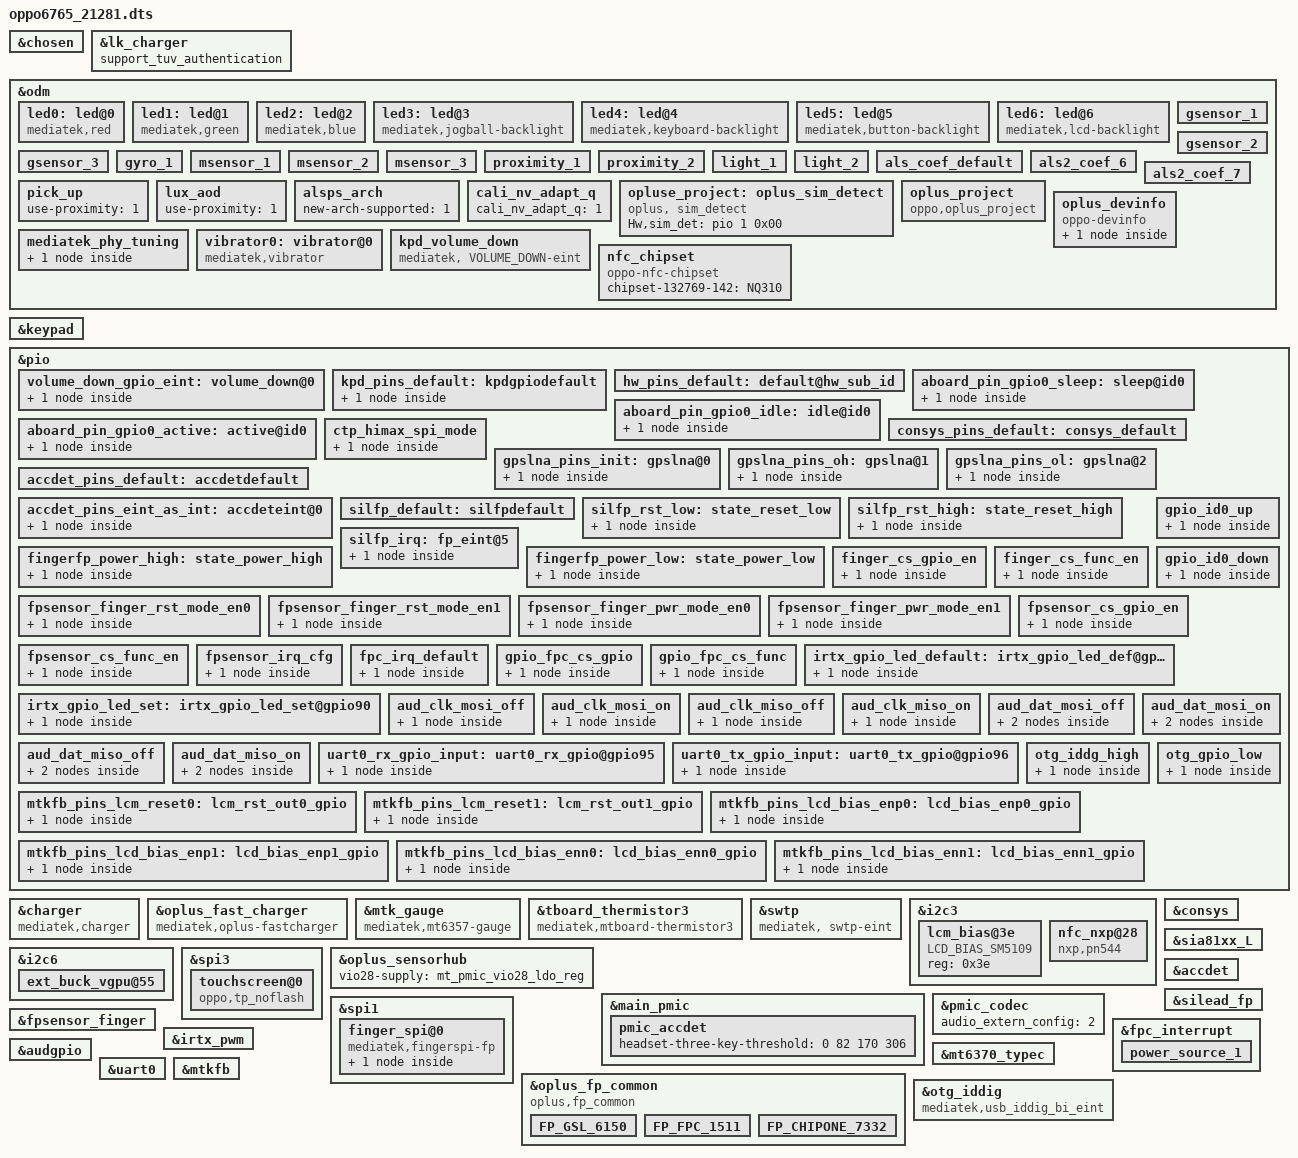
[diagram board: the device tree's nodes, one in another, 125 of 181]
// SPDX-License-Identifier: GPL-2.0+
/*
 * Copyright (c) 2019 MediaTek Inc.
 *
 */

#include <dt-bindings/interrupt-controller/arm-gic.h>
#include <dt-bindings/interrupt-controller/irq.h>
#include <dt-bindings/pinctrl/mt6765-pinfunc.h>
#include <dt-bindings/clock/mt6765-clk.h>

/dts-v1/;
/plugin/;

/* chosen */
&chosen {

	/* fpga may has no lk, we need to specify display info here */
	/* fb buffer is reserved using this dts by memory node above */
	atag,videolfb-fb_base_h = <0x0>;
	atag,videolfb-fb_base_l = <0x5e605000>;
	atag,videolfb-islcmfound = <1>;
	/* because no lk, so lcm is not inited */
	atag,videolfb-islcm_inited = <0>;
	atag,videolfb-fps= <6000>;
	atag,videolfb-vramSize= <0x017bb000>;
	atag,videolfb-lcmname= "nt35695B_fhd_dsi_cmd_auo_rt5081_drv";
};

&lk_charger{
	support_tuv_authentication;
};

&odm {
	led0:led@0 {
		compatible = "mediatek,red";
		led_mode = <0>;
		data = <1>;
		pwm_config = <0 0 0 0 0>;
	};
	led1:led@1 {
		compatible = "mediatek,green";
		led_mode = <0>;
		data = <1>;
		pwm_config = <0 0 0 0 0>;
	};
	led2:led@2 {
		compatible = "mediatek,blue";
		led_mode = <0>;
		data = <1>;
		pwm_config = <0 0 0 0 0>;
	};
	led3:led@3 {
		compatible = "mediatek,jogball-backlight";
		led_mode = <0>;
		data = <1>;
		pwm_config = <0 0 0 0 0>;
	};
	led4:led@4 {
		compatible = "mediatek,keyboard-backlight";
		led_mode = <0>;
		data = <1>;
		pwm_config = <0 0 0 0 0>;
	};
	led5:led@5 {
		compatible = "mediatek,button-backlight";
		led_mode = <0>;
		data = <1>;
		pwm_config = <0 0 0 0 0>;
	};
	led6:led@6 {
		compatible = "mediatek,lcd-backlight";
//#ifndef OPLUS_BUG_STABILITY
		//led_mode = <5>;
//#else
		led_mode = <4>;
//#endif
		data = <1>;
		pwm_config = <0 3 0 0 0>;
	};
/*sensor start */
	/*
	enum {
		LIS3DH,
		LSM6DS3,
		BMI160,
		LIS2HH12,
		LSM6DSM,
		BMI2XY,
		LSM6DSO,
		BMA2X2,
		KX022,
		SC7A20,
		MC34X9,
		STK832X,
		BMA4XY,
	};
	*/
    gsensor_1: gsensor_1 {
		status = "okay";
		sensor_name = <9>;//SC7A20
		i2c_num = <0>;
		i2c_addr = <0x11>;
		direction = <1>;
		eint_num = <12>;
		step_count_7_en = <1>;
		config_miso = <1>;
		correct_y_bias = <1>;
	};
	gsensor_2: gsensor_2 {
		status = "okay";
		sensor_name = <3>;//LIS2HH12
		i2c_num = <0>;
		i2c_addr = <0x68>;
		direction = <3>;
		eint_num = <12>;
		step_count_7_en = <1>;
		config_miso = <1>;
		correct_y_bias = <1>;
	};
	gsensor_3: gsensor_3 {
		status = "okay";
		sensor_name = <0>;//LIS3DH
		i2c_num = <0>;
		i2c_addr = <0x68>;
		direction = <0>;
		eint_num = <12>;
		step_count_7_en = <1>;
		config_miso = <1>;
		correct_y_bias = <1>;
	};
	gyro_1: gyro_1 {
		status = "okay";
		sensor_name = <12>;//BMA4XY
		i2c_num = <0>;
		i2c_addr = <0x68>;
		direction = <10>;
		eint_num = <12>;
		step_count_7_en = <1>;
		config_miso = <1>;
		correct_y_bias = <1>;
	};
	/*
	enum {
		AKM09911,
		MMC3530,
		MMC5603,
		MXG4300,
		AF6133,
	};
	*/
	msensor_1: msensor_1 {
		status = "okay";
		sensor_name = <0>;//AKM09918
		i2c_num = <0>;
		i2c_addr = <0x0c>;
		direction = <1>;
		eint_num = <0>;
	};

	msensor_2: msensor_2 {
		status = "okay";
		sensor_name = <2>;//MMC5603
		i2c_num = <0>;
		i2c_addr = <0x30>;
		direction = <1>;
		eint_num = <0>;
	};
	msensor_3: msensor_3 {
		status = "okay";
		sensor_name = <1>;//MMC3530
		i2c_num = <0>;
		i2c_addr = <0x30>;
		direction = <3>;
		eint_num = <0>;
	};
	/*
	enum {
		TMD2725,
		APSD9922,
		STK3335,
		STK3331,
		STK2232,
		TCS3701,
		STK32600,
		STK33502,
	};
	*/
	proximity_1: proximity_1 {
		status = "okay";
		sensor_name = <7>;//STK33502
		i2c_num = <0>;
		i2c_addr = <0x46>;
		direction = <4>;
		eint_num = <6>;
		low_step = <300>;
		high_step = <400>;
		low_limit = <650>;
		high_limit = <1050>;
		dirty_low_step = <300>;
		dirty_high_step = <400>;
		ps_dirty_limit = <1800>;
		ps_ir_limit = <2000>;
		ps_adjust_min = <0>;
		ps_adjust_max = <1850>;
		sampling_count = <5>;
		step_max = <400>;
		step_min = <100>;
		step_div = <2000>;
		anti_shake_delta = <70>;
		dynamic_cali_max = <2000>;
		raw2offset_radio = <1000>;
		offset_max = <60000>;
		offset_range_min = <0>;
		offset_range_max = <65534>;
		force_cali_limit = <2000>;
		cali_jitter_limit = <20>;
		cal_offset_margin = <3000>;
	};
	proximity_2: proximity_2 {
		status = "okay";
		sensor_name = <3>;//STK3331
		i2c_num = <0>;
		i2c_addr = <71>;
		direction = <4>;
		eint_num = <10>;
		low_step = <300>;
		high_step = <400>;
		low_limit = <650>;
		high_limit = <1050>;
		dirty_low_step = <200>;
		dirty_high_step = <300>;
		ps_dirty_limit = <1800>;
		ps_ir_limit = <2000>;
		ps_adjust_min = <0>;
		ps_adjust_max = <1850>;
		sampling_count = <5>;
		step_max = <400>;
		step_min = <100>;
		step_div = <1500>;
		anti_shake_delta = <80>;
		dynamic_cali_max = <5000>;
		raw2offset_radio = <1000>;
		offset_max = <60000>;
		offset_range_min = <0>;
		offset_range_max = <65534>;
		force_cali_limit = <2000>;
		cali_jitter_limit = <20>;
		cal_offset_margin = <3000>;
		parameter-number = <4>;
		sensor-reg  = <0x03 0xC0
				0xA1 0x0E>;
	};
	light_1: light_1 {
		status = "okay";
		sensor_name = <7>;//STK33502
		i2c_num = <0>;
		i2c_addr = <0x46>;
		direction = <4>;
		eint_num = <6>;
		als_ratio = <65>;
		als_buffer_length =<8>;
		als_type = <1>;//<1-normal;2-under screen;3-normal needed compensation>
		device_name = "stk33502";
	};
	light_2: light_2 {
		status = "okay";
		sensor_name = <3>;//STK3331
		i2c_num = <0>;
		i2c_addr = <71>;
		direction = <4>;
		eint_num = <10>;
		als_ratio = <200>;
		device_name = "stk3331";
		als_buffer_length =<5>;
		als_type = <1>;
	};
	als_coef_default:als_coef_default{
		status = "okay";
		coef_A = <8400>;
		coef_B = <34500>;
		coef_C = <900>;
		coef_D = <2300>;
		coef_E = <12000>;
        };
	als2_coef_6:als2_coef_6 {
		status = "okay";
		coef_A = <20000>;
		coef_B = <68400>;
		coef_C = <3800>;
		coef_D = <12300>;
		coef_E = <17000>;
	};
	als2_coef_7:als2_coef_7 {
		status = "okay";
		coef_A = <30000>;
		coef_B = <68400>;
		coef_C = <3800>;
		coef_D = <12300>;
		coef_E = <17000>;
	};
	pick_up: pick_up {
		status = "okay";
		use-proximity = <1>;
	};
	lux_aod: lux_aod {
		status = "okay";
		use-proximity = <1>;
	};
	alsps_arch: alsps_arch {
		status = "okay";
		new-arch-supported = <1>;
	};
	cali_nv_adapt_q: cali_nv_adapt_q {
		status = "okay";
		cali_nv_adapt_q = <1>;
	};
/*sensor end */
/*VNDOR_EDIT oppo project start */
	opluse_project:oplus_sim_detect {
		compatible = "oplus, sim_detect";
		Hw,sim_det = <&pio 1 0x00>;
	};

	oplus_project:oplus_project {
		compatible = "oppo,oplus_project";
	};

	oplus_devinfo:oplus_devinfo {
		compatible = "oppo-devinfo";
		main-sub {
			use_tristate_gpio;
			compatible = "hw-match, main-sub";
			aboard-gpio0 = <&pio 160 0x00>;
			aboard-patterns = <0 1 0 0>;
			/*main board*/
			match-projects = <21281 21282 21283 21285>;
		};
	};
/*2021/04/21, Add eye diag parameter */
	mediatek_phy_tuning:mediatek_phy_tuning {
		phy_tuning {
			compatible = "mediatek,phy_eye";
			device_vrt_ref = <7>;
			device_term_ref = <7>;
			device_rev6_ref = <3>;
			host_vrt_ref = <7>;
			host_term_ref = <2>;
			host_rev6_ref = <3>;
	};
};
/*2021/04/21, Add eye diag parameter */
	vibrator0:vibrator@0 {
		compatible = "mediatek,vibrator";
		/*
		vib_timer = <25>;
		vib_limit = <9>;
		vib_vol= <9>;
		*/
		vib_timer = <30>;
		vib_limit = <0>;
		vib_vol= <11>;
	};
//ifdef OPLUS_BUG_STABILITY
	kpd_volume_down:kpd_volume_down {
		compatible = "mediatek, VOLUME_DOWN-eint";
		interrupt-parent = <&pio>;
		interrupts = <94 IRQ_TYPE_EDGE_FALLING 94 0>;
		debounce = <32000>;
		status = "okay";
	};
//#endif /*OPLUS_BUG_STABILITY*/

//#ifdef OPLUS_FEATURE_NFC_CONSOFT
    nfc_chipset:nfc_chipset {
        compatible = "oppo-nfc-chipset";
        chipset-132769-142 = "NQ310";
    };
//#endif /* OPLUS_FEATURE_NFC_CONSOFT */
};
//ifdef OPLUS_BUG_STABILITY
&keypad {
	keypad,volume-down	= <&pio 94 0x00>;
        pinctrl-names = "default", "volume_down_as_int";
        pinctrl-0 = <&kpd_pins_default>;
        pinctrl-1 = <&volume_down_gpio_eint>;
	status = "okay";
};

&pio {
	volume_down_gpio_eint:volume_down@0{
		pins_cmd_dat {
			pinmux = <PINMUX_GPIO94__FUNC_GPIO94>;
			slew-rate = <0>;  /*direction 0:in, 1:out*/
			input-enable;
		};
	};
	kpd_pins_default: kpdgpiodefault {
                pins_cmd_dat {
                        pinmux = <PINMUX_GPIO93__FUNC_KPCOL0>;
                        bias-pull-up = <MTK_PUPD_SET_R1R0_10>;
                        output-low;
                        input-schmitt-enable;
                };
        };
};
//#endif /*OPLUS_BUG_STABILITY*/

&oplus_devinfo {
	pinctrl-names = "default", "aboard_gpio0_sleep", "aboard_gpio0_active", "aboard_gpio0_idle";
	pinctrl-0 = <&hw_pins_default>;
	pinctrl-1 = <&aboard_pin_gpio0_sleep>;
	pinctrl-2 = <&aboard_pin_gpio0_active>;
	pinctrl-3 = <&aboard_pin_gpio0_idle>;
};

&pio {
	hw_pins_default:default@hw_sub_id {
	};

	aboard_pin_gpio0_sleep:sleep@id0 {
		pins_cmd_dat {
			pinmux = <PINMUX_GPIO160__FUNC_GPIO160>;
			input;
			bias-pull-down;
			input-enable;
		};
	};

	aboard_pin_gpio0_active:active@id0 {
		pins_cmd_dat {
			pinmux = <PINMUX_GPIO160__FUNC_GPIO160>;
			input;
			bias-pull-up;
			input-enable;
		};
	};

	aboard_pin_gpio0_idle:idle@id0 {
		pins_cmd_dat {
			pinmux = <PINMUX_GPIO160__FUNC_GPIO160>;
			slew-rate = <0>;
			bias-disable;
			input-enable;
		};
	};
};

//#idef OPLUS_CHARGER_BASIC
&charger {
	compatible = "mediatek,charger";
		//pinctrl-names = "default", "charger_gpio_as_output_low", "charger_gpio_as_output_high", "ship_sleep", "ship_active", "shortc_active";
		//pinctrl-0 = <&charger_pins_default>;
		//pinctrl-1 = <&charger_pins_eint_output0>;
		//pinctrl-2 = <&charger_pins_eint_output1>;
		//pinctrl-3 = <&ship_sleep_gpio>;
		//pinctrl-4 = <&ship_active_gpio>;
		//pinctrl-5 = <&shortc_active_gpio>;

		//for oppo chg framework:
		qcom,input_current_charger_ma = <2000>;
		qcom,input_current_cdp_ma = <1500>;
		qcom,input_current_usb_ma = <500>;
		qcom,input_current_led_ma = <1200>;
		qcom,input_current_led_ma_forcmcc = <500>;
		qcom,input_current_camera_ma = <1200>;
		qcom,input_current_calling_ma = <1200>;
		
		qcom,input_current_led_ma_high = <1200>;
		qcom,input_current_led_ma_warm = <1500>;
		qcom,input_current_led_ma_normal = <2000>;

		qcom,led_high_bat_decidegc = <370>;
		qcom,led_warm_bat_decidegc = <350>;

		qcom,iterm_disabled = <0>;
		qcom,iterm_ma = <205>;
		qcom,recharge-mv = <100>;

		qcom,batt_capacity_mah = <4230>; /*typical capacity*/
		//qcom,batt_capacity_mah = <3900>; /*rated capacity*/

		qcom,removed_bat_decidegc = <190>;  /* < -19C */

		qcom,cold_bat_decidegc = <20>;  /* -2C ~ 0C */
		qcom,temp_cold_vfloat_mv = <3980>;
		qcom,temp_cold_fastchg_current_ma = <350>;

		qcom,little_cold_bat_decidegc = <0>;	/* 0C ~ 5C */
		qcom,temp_little_cold_vfloat_mv = <4385>;
		qcom,temp_little_cold_fastchg_current_ma_high = <550>;
		qcom,temp_little_cold_fastchg_current_ma_low = <550>;
		qcom,temp_little_cold_fastchg_current_ma = <550>;
		monet,temp_little_cold_usbchg_current_ma_high = <650>;
		monet,temp_little_cold_usbchg_current_ma_low = <650>;
		monet,temp_little_cold_usbchg_current_ma = <650>;

		qcom,cool_bat_decidegc = <50>;	/* 5C ~ 12C */
		qcom,temp_cool_vfloat_mv = <4385>;
		qcom,temp_cool_fastchg_current_ma_high = <1150>;
		qcom,temp_cool_fastchg_current_ma_low = <550>;
		monet,temp_cool_usbchg_current_ma_high = <650>;
		monet,temp_cool_usbchg_current_ma_low = <550>;

		qcom,little_cool_bat_decidegc = <120>;	/* 12C ~ 16C */
		qcom,temp_little_cool_vfloat_mv = <4385>;
		qcom,temp_little_cool_fastchg_current_ma = <1700>;
		monet,temp_little_cool_usbchg_current_ma = <550>;

		qcom,normal_bat_decidegc = <160>;	/* 16C ~ 45C */
		qcom,temp_normal_fastchg_current_ma = <2200>;
		monet,temp_normal_usbchg_current_ma = <550>;
		qcom,temp_normal_vfloat_mv = <4385>;

		qcom,warm_bat_decidegc = <440>;		/* 44C ~ 53C */ /*8pin Bat Vooc project need add 3 degree C*/
		qcom,temp_warm_vfloat_mv = <4130>;
		qcom,temp_warm_fastchg_current_ma = <1150>;
		monet,temp_warm_usbchg_current_ma = <550>;
		qcom,temp_warm_fastchg_current_ma_led_on = <500>;

		qcom,hot_bat_decidegc = <530>;  /* > 53C */

		qcom,non_standard_vfloat_mv = <3980>;
		qcom,non_standard_fastchg_current_ma = <512>;

		qcom,short_c_bat_cv_mv = <4330>;
		qcom,short_c_bat_vfloat_mv = <3800>;
		qcom,short_c_bat_fastchg_current_ma = <512>;
		qcom,short_c_bat_vfloat_sw_limit = <3750>;

		qcom,cold_vfloat_sw_limit = <3930>;
		qcom,little_cold_vfloat_sw_limit = <4335>;
		qcom,cool_vfloat_sw_limit = <4335>;
		qcom,little_cool_vfloat_sw_limit = <4335>;
		qcom,normal_vfloat_sw_limit = <4335>;
		qcom,warm_vfloat_sw_limit = <4080>;
		qcom,non_standard_vfloat_sw_limit = <3930>;

		qcom,max_chg_time_sec = <36000>;
		qcom,charger_hv_thr = <5800>;
		qcom,charger_recv_thr = <5800>;
		qcom,charger_lv_thr = <3400>;
		qcom,vbatt_full_thr = <4400>;
		qcom,vbatt_hv_thr = <4500>;

		qcom,vfloat_step_mv = <10>;
		qcom,non_standard_vfloat_over_sw_limit = <4000>;
		qcom,cold_vfloat_over_sw_limit = <4000>;
		qcom,little_cold_vfloat_over_sw_limit = <4400>;
		qcom,cool_vfloat_over_sw_limit = <4400>;
		qcom,little_cool_vfloat_over_sw_limit = <4400>;
		qcom,normal_vfloat_over_sw_limit = <4400>;
		qcom,warm_vfloat_over_sw_limit = <4150>;

		qcom,vbatt_power_off = <3300>;
		qcom,vbatt_soc_1 = <3410>;
		qcom,vooc_project = <0>;
		qcom,vbatt_num = <1>;

		qcom,normal_vterm_hw_inc = <150>;
		qcom,non_normal_vterm_hw_inc = <10>;

		qcom,ff1_normal_fastchg_ma = <1088>;
		qcom,ffc2_normal_fastchg_ma = <780>;/*16C~35c*/
		qcom,ffc2_temp_warm_decidegc = <350>;
		qcom,ffc2_warm_fastchg_ma = <840>;/*35C~40c*/
		qcom,ffc2_temp_high_decidegc = <400>;
		qcom,ffc2_temp_low_decidegc = <120>;
		qcom,ff1_exit_step_ma = <488>;
		qcom,ff1_warm_exit_step_ma = <418>;
		qcom,ffc2_exit_step_ma = <180>;
		qcom,ffc2_warm_exit_step_ma = <170>;

		qcom,ffc_normal_vfloat_sw_limit = <4430>;
		qcom,ffc_temp_normal_vfloat_mv = <4500>;
		qcom,ffc_normal_vfloat_over_sw_limit = <4500>;

		qcom,default_iterm_ma = <205>;
		qcom,default_temp_normal_fastchg_current_ma = <2200>;
		qcom,default_normal_vfloat_sw_limit = <4335>;
		qcom,default_temp_normal_vfloat_mv = <4385>;
		qcom,default_normal_vfloat_over_sw_limit = <4400>;

		//for 2nd chip:
		qcom,iterm_ma_2nd = <300>;
		qcom,recharge-mv_2nd = <121>;

		qcom,temp_little_cold_vfloat_mv_2nd = <4391>;	/* 0C ~ 5C */
		qcom,temp_cool_vfloat_mv_2nd = <4391>;	/* 5C ~ 12C */
		qcom,temp_little_cool_vfloat_mv_2nd = <4391>;	/* 12C ~ 16C */
		qcom,temp_normal_vfloat_mv_2nd = <4391>;	/* 16C ~ 45C */

		qcom,little_cold_vfloat_over_sw_limit_2nd = <4395>;
		qcom,cool_vfloat_over_sw_limit_2nd = <4395>;
		qcom,little_cool_vfloat_over_sw_limit_2nd = <4395>;
		qcom,normal_vfloat_over_sw_limit_2nd = <4395>;

		qcom,default_iterm_ma_2nd = <300>;
		qcom,default_temp_normal_vfloat_mv_2nd = <4391>;
		qcom,default_normal_vfloat_over_sw_limit_2nd = <4395>;

		//for control:
		//qcom,suspend_after_full;
		qcom,check_batt_full_by_sw;
		//qcom,external_gauge;
		qcom,chg_ctrl_by_calling;
		qcom,chg_ctrl_by_lcd;
		qcom,chg_ctrl_by_camera;
		qcom,sw_vfloat_over_protect_enable;
		//qcom,ffc_support;

		//GPIO config:
		//qcom,chargerid_switch-gpio = <&pio 97 0x00>;
		//qcom,ship-gpio = <&pio 155 0x00>;
		//qcom,shortc-gpio = <&pio 77 0x00>;
};

&oplus_fast_charger {
	compatible = "mediatek,oplus-fastcharger";
		//pinctrl-names = "default", "charger_gpio_as_output_low", "charger_gpio_as_output_high", "ship_sleep", "ship_active", "shortc_active";
		//pinctrl-0 = <&charger_pins_default>;
		//pinctrl-1 = <&charger_pins_eint_output0>;
		//pinctrl-2 = <&charger_pins_eint_output1>;
		//pinctrl-3 = <&ship_sleep_gpio>;
		//pinctrl-4 = <&ship_active_gpio>;
		//pinctrl-5 = <&shortc_active_gpio>;

		//for oppo chg framework:
		qcom,input_current_charger_ma = <2000>;
		qcom,input_current_cdp_ma = <1500>;
		qcom,input_current_usb_ma = <500>;
		qcom,input_current_led_ma = <1200>;
		qcom,input_current_led_ma_forcmcc = <500>;
		qcom,input_current_camera_ma = <1200>;
		qcom,input_current_calling_ma = <1200>;

		qcom,input_current_led_ma_high = <1000>;
		qcom,input_current_led_ma_warm = <1500>;
		qcom,input_current_led_ma_normal = <2000>;

		qcom,led_high_bat_decidegc = <370>;
		qcom,led_warm_bat_decidegc = <340>;

		qcom,iterm_disabled = <0>;
		qcom,iterm_ma = <265>;
		qcom,recharge-mv = <115>;

		qcom,batt_capacity_mah = <5000>; /*typical capacity*/
		//qcom,batt_capacity_mah = <3900>; /*rated capacity*/

		qcom,removed_bat_decidegc = <190>;  /* < -19C */

		qcom,cold_bat_decidegc = <20>;  /* -2C ~ 0C */
		qcom,temp_cold_vfloat_mv = <3980>;
		qcom,temp_cold_fastchg_current_ma = <350>;

		qcom,little_cold_bat_decidegc = <0>;	/* 0C ~ 5C */
		qcom,temp_little_cold_vfloat_mv = <4435>;
		qcom,temp_little_cold_fastchg_current_ma_high = <650>;
		qcom,temp_little_cold_fastchg_current_ma_low = <650>;
		qcom,temp_little_cold_fastchg_current_ma = <650>;
		monet,temp_little_cold_usbchg_current_ma_high = <650>;
		monet,temp_little_cold_usbchg_current_ma_low = <650>;
		monet,temp_little_cold_usbchg_current_ma = <650>;

		qcom,cool_bat_decidegc = <50>;	/* 5C ~ 12C */
		qcom,temp_cool_vfloat_mv = <4435>;
		qcom,temp_cool_fastchg_current_ma_high = <1350>;
		qcom,temp_cool_fastchg_current_ma_low = <650>;
		monet,temp_cool_usbchg_current_ma_high = <650>;
		monet,temp_cool_usbchg_current_ma_low = <550>;

		qcom,little_cool_bat_decidegc = <120>;	/* 12C ~ 16C */
		qcom,temp_little_cool_vfloat_mv = <4435>;
		qcom,temp_little_cool_fastchg_current_ma = <2050>;
		monet,temp_little_cool_usbchg_current_ma = <550>;

		qcom,normal_bat_decidegc = <160>;	/* 16C ~ 45C */
		qcom,temp_normal_fastchg_current_ma = <2200>;
		monet,temp_normal_usbchg_current_ma = <550>;
		qcom,temp_normal_vfloat_mv = <4435>;

		qcom,warm_bat_decidegc = <450>;		/* 45C ~ 53C */ /*8pin Bat Vooc project need add 3 degree C*/
		qcom,temp_warm_vfloat_mv = <4130>;
		qcom,temp_warm_fastchg_current_ma = <1350>;
		monet,temp_warm_usbchg_current_ma = <550>;
		qcom,temp_warm_fastchg_current_ma_led_on = <500>;

		qcom,hot_bat_decidegc = <530>;  /* > 53C */

		qcom,non_standard_vfloat_mv = <3980>;
		qcom,non_standard_fastchg_current_ma = <512>;

		qcom,short_c_bat_cv_mv = <4330>;
		qcom,short_c_bat_vfloat_mv = <3800>;
		qcom,short_c_bat_fastchg_current_ma = <512>;
		qcom,short_c_bat_vfloat_sw_limit = <3750>;

		qcom,cold_vfloat_sw_limit = <3930>;
		qcom,little_cold_vfloat_sw_limit = <4380>;
		qcom,cool_vfloat_sw_limit = <4380>;
		qcom,little_cool_vfloat_sw_limit = <4380>;
		qcom,normal_vfloat_sw_limit = <4380>;
		qcom,warm_vfloat_sw_limit = <4080>;
		qcom,non_standard_vfloat_sw_limit = <3930>;

		qcom,max_chg_time_sec = <36000>;
		qcom,charger_hv_thr = <9800>;
		qcom,charger_recv_thr = <9800>;
		qcom,charger_lv_thr = <3400>;
		qcom,vbatt_full_thr = <4400>;
		qcom,vbatt_hv_thr = <4550>;

		qcom,vfloat_step_mv = <10>;
		qcom,non_standard_vfloat_over_sw_limit = <4000>;
		qcom,cold_vfloat_over_sw_limit = <4000>;
		qcom,little_cold_vfloat_over_sw_limit = <4450>;
		qcom,cool_vfloat_over_sw_limit = <4450>;
		qcom,little_cool_vfloat_over_sw_limit = <4450>;
		qcom,normal_vfloat_over_sw_limit = <4450>;
		qcom,warm_vfloat_over_sw_limit = <4150>;

		qcom,vbatt_power_off = <3300>;
		qcom,vbatt_soc_1 = <3410>;
		qcom,vooc_project = <0>;
		qcom,vbatt_num = <1>;

		qcom,normal_vterm_hw_inc = <150>;
		qcom,non_normal_vterm_hw_inc = <10>;

		qcom,ff1_normal_fastchg_ma = <1088>;
		qcom,ffc2_normal_fastchg_ma = <780>;/*16C~35c*/
		qcom,ffc2_temp_warm_decidegc = <350>;
		qcom,ffc2_warm_fastchg_ma = <840>;/*35C~40c*/
		qcom,ffc2_temp_high_decidegc = <400>;
		qcom,ffc2_temp_low_decidegc = <120>;
		qcom,ff1_exit_step_ma = <488>;
		qcom,ff1_warm_exit_step_ma = <418>;
		qcom,ffc2_exit_step_ma = <180>;
		qcom,ffc2_warm_exit_step_ma = <170>;

		qcom,ffc_normal_vfloat_sw_limit = <4430>;
		qcom,ffc_temp_normal_vfloat_mv = <4500>;
		qcom,ffc_normal_vfloat_over_sw_limit = <4500>;

		qcom,default_iterm_ma = <265>;
		qcom,default_temp_normal_fastchg_current_ma = <2200>;
		qcom,default_normal_vfloat_sw_limit = <4380>;
		qcom,default_temp_normal_vfloat_mv = <4435>;
		qcom,default_normal_vfloat_over_sw_limit = <4450>;

		//for 2nd chip:
		qcom,iterm_ma_2nd = <300>;
		qcom,recharge-mv_2nd = <121>;

		qcom,temp_little_cold_vfloat_mv_2nd = <4391>;	/* 0C ~ 5C */
		qcom,temp_cool_vfloat_mv_2nd = <4391>;	/* 5C ~ 12C */
		qcom,temp_little_cool_vfloat_mv_2nd = <4391>;	/* 12C ~ 16C */
		qcom,temp_normal_vfloat_mv_2nd = <4391>;	/* 16C ~ 45C */

		qcom,little_cold_vfloat_over_sw_limit_2nd = <4395>;
		qcom,cool_vfloat_over_sw_limit_2nd = <4395>;
		qcom,little_cool_vfloat_over_sw_limit_2nd = <4395>;
		qcom,normal_vfloat_over_sw_limit_2nd = <4395>;

		qcom,default_iterm_ma_2nd = <300>;
		qcom,default_temp_normal_vfloat_mv_2nd = <4391>;
		qcom,default_normal_vfloat_over_sw_limit_2nd = <4395>;

		//for control:
		//qcom,suspend_after_full;
		qcom,check_batt_full_by_sw;
		//qcom,external_gauge;
		qcom,chg_ctrl_by_calling;
		qcom,chg_ctrl_by_lcd;
		qcom,chg_ctrl_by_camera;
		qcom,sw_vfloat_over_protect_enable;
		//qcom,ffc_support;

		//GPIO config:
		//qcom,chargerid_switch-gpio = <&pio 97 0x00>;
		//qcom,ship-gpio = <&pio 155 0x00>;
		//qcom,shortc-gpio = <&pio 77 0x00>;

		qcom,vbatt_pdqc_to_5v_thr = <4420>;
		status = "okay";
};

&mtk_gauge {
	compatible = "mediatek,mt6357-gauge";
	charger = <&mt6370_chg>;
	bootmode = <&chosen>;
	io-channels = <&pmic_auxadc 0x03>,
		<&pmic_auxadc 0x01>,
		<&pmic_auxadc 0x0e>,
		<&pmic_auxadc 0x0f>,
		<&pmic_auxadc 0x10>,
		<&auxadc 3>;
	io-channel-names = "pmic_battery_temp",
		"pmic_battery_voltage",
		"pmic_bif_voltage",
		"pmic_ptim_voltage",
		"pmic_ptim_r",
		"auxadc6-batt_id_v";
	nvmem-cells = <&fg_init>, <&fg_soc>;
	FUELGAGUE_APPLY = <(1)>;
	Enable_Battery_Temp_Compensation = <(1)>;
	Enable_Is_Force_Full = <1>;
	RBAT_PULL_UP_R = <(12000)>;
	RBAT_PULL_UP_VOLT = <(1800)>;
	status = "okay";
};
//#endif /* OPLUS_CHARGER_BASIC */

&tboard_thermistor3{
		compatible = "mediatek,mtboard-thermistor3";
		io-channels = <&auxadc 4>;
		io-channel-names = "thermistor-ch2";
		interconnects = <&auxadc 4>;
		use_new_ntc_table;
};

//#ifdef OPLUS_BUG_COMPATIBILITY
&swtp {
		compatible = "mediatek, swtp-eint";
	};
//#endif /*OPLUS_BUG_COMPATIBILITY*/

&i2c3 {
//#ifndef OPLUS_BUG_STABILITY
//	ext_buck_lp4@57 {
//		regulator-name ="ext_buck_vdd2";
//		regulator-min-microvolt = <300000>;
//		regulator-max-microvolt = <1300000>;
//		vsel_pin = <0>;
//	};
//
//	ext_buck_lp4x@50 {
//		regulator-name ="ext_buck_vddq";
//		regulator-min-microvolt = <300000>;
//		regulator-max-microvolt = <1300000>;
//		vsel_pin = <1>;
//	};
//#else
	lcm_bias@3e{
		   compatible = "LCD_BIAS_SM5109","LCD_BIAS_OCP2130";
		   reg = <0x3e>;
		   status = "okay";
	};
//#endif
};

//#ifdef OPLUS_FEATURE_NFC_BRINGUP
&i2c3 {
       status = "okay";
       nfc_nxp@28 {
               compatible = "nxp,pn544";
               reg = <0x28>;
               nxp,pn544-irq = <&pio 97 0x0>;
               nxp,pn544-ven = <&pio 98 0x0>;
               nxp,pn544-fw-dwnld = <&pio 170 0x0>;
               //pn544-clkreq = <&pio 89 0x0>;
               interrupt-parent = <&pio>;
       };
};
//#endif /* OPLUS_FEATURE_NFC_BRINGUP */

&i2c6 {
	ext_buck_vgpu@55 {
		regulator-name ="ext_buck_vgpu";
		regulator-min-microvolt = <300000>;
		regulator-max-microvolt = <1300000>;
		vsel_pin = <2>;
	};
};

/* TOUCH start */

&spi3 {
	status = "ok";
  	touchscreen@0 {
		compatible = "oppo,tp_noflash";
		reg = <0>; //Same as CS ID
		chip-name = "OPPO_TP_NOFLASH";
		status = "ok";

        //chip_name_ilitek_9882n = "NF_ILI9881H";

		spi-max-frequency = <9600000>;
		interrupt-parent = <&pio>;
		interrupts = <0 IRQ_TYPE_EDGE_FALLING 0 0>;
		irq-gpio = <&pio 0 0x2002>;
		reset-gpio = <&pio 174 0>;

		platform_support_project = <21281 21282 21283>;
		platform_support_project_dir = <21281 21281 21281>;
		platform_support_project_commandline = "default_commandline", "default_commandline", "default_commandline";

		touchpanel,max-num-support = <10>;
		touchpanel,tx-rx-num = <18 32>;
		touchpanel,panel-coords = <720 1600>;
		touchpanel,display-coords = <720 1600>;
		touchpanel,touchmajor-limit = <0 54>;

		pinctrl-names = "default";
		pinctrl-0 = <&ctp_himax_spi_mode>;

		incell_screen;
		fw_edge_limit_support;
		black_gesture_support;
		charger_pump_support;
		headset_pump_support;
		esd_handle_support;
		//spurious_fingerprint_support;
		//lcd_trigger_fp_check;
		black_gesture_test_support;
		noflash_support;
		smart_gesture_support;
		pressure_report_support;
		fw_update_app_support;
		game_switch_support;
		drlimit_remove_support;
		lcd_trigger_load_tp_fw_support;
		freq_hop_simulate_support;
		suspend_gesture_cfg;
		fw_update_in_probe_with_headfile;

		touchpanel,button-type = <4>;
	};
};

&pio {
	ctp_himax_spi_mode: ctp_himax_spi_mode {
		pins_cmd_dat {
			pinmux = <PINMUX_GPIO21__FUNC_SPI3_MI>,
				<PINMUX_GPIO22__FUNC_SPI3_CSB>,
				<PINMUX_GPIO23__FUNC_SPI3_MO>,
				<PINMUX_GPIO24__FUNC_SPI3_CLK>;
			drive-strength = <2>;
		};
	};
};
/* TOUCH end */

/* CONSYS GPIO standardization */
&pio {
	consys_pins_default: consys_default {
	};
	gpslna_pins_init: gpslna@0 {
		pins_cmd_dat {
			pinmux = <PINMUX_GPIO91__FUNC_GPIO91>;
			slew-rate = <0>;
			bias-disable;
			output-low;
		};
	};
	gpslna_pins_oh: gpslna@1 {
		pins_cmd_dat {
			pinmux = <PINMUX_GPIO91__FUNC_GPIO91>;
			slew-rate = <1>;
			output-high;
		};
	};
	gpslna_pins_ol: gpslna@2 {
		pins_cmd_dat {
			pinmux = <PINMUX_GPIO91__FUNC_GPIO91>;
			slew-rate = <1>;
			output-low;
		};
	};
};

//#ifdef OPLUS_FEATURE_SENSOR
&oplus_sensorhub{
	vio28-supply = <&mt_pmic_vio28_ldo_reg>;
	status = "okay";
};
//#endif //OPLUS_FEATURE_SENSOR

&consys {
	pinctrl-names = "default", "gps_lna_state_init",
		"gps_lna_state_oh", "gps_lna_state_ol";
	pinctrl-0 = <&consys_pins_default>;
	pinctrl-1 = <&gpslna_pins_init>;
	pinctrl-2 = <&gpslna_pins_oh>;
	pinctrl-3 = <&gpslna_pins_ol>;
	status = "okay";
};
/* CONSYS end */

&main_pmic {
    pmic_accdet: pmic_accdet {
        headset-three-key-threshold = <0 82 170 306>;
    };
};

&pmic_codec {
	/* this dtsi config for product's special config, AudioHal read ctl 'OPLUS_AUDIO_EXTERN_CONFIG' get the values*
	 * 1st value --> PA type: 0:NXP Pa, 1:Awinic Pa 2:sia81xx Pa*/
	audio_extern_config = <2>;
};

//#ifdef VENDOR_EDIT
&sia81xx_L{
	si,sia_boost_vol_support = <1>;
	sia81xx_audio_extern_config = <2>;
};
//endif

/* accdet start */
&accdet {
	accdet-mic-vol = <6>;
	headset-mode-setting = <0x500 0x500 1 0x1f0 0x800 0x800 0x20 0x44>;
	accdet-plugout-debounce = <1>;
	accdet-mic-mode = <1>;
	headset-eint-level-pol = <8>;
	headset-three-key-threshold = <0 80 220 400>;
	headset-three-key-threshold-CDD = <0 121 192 600>;
	headset-four-key-threshold = <0 58 121 192 400>;
	pinctrl-names = "default", "state_eint_as_int";
	pinctrl-0 = <&accdet_pins_default>;
	pinctrl-1 = <&accdet_pins_eint_as_int>;
	status = "okay";
};
&pio {
	accdet_pins_default: accdetdefault {
	};
	accdet_pins_eint_as_int: accdeteint@0 {
		pins_cmd_dat {
			pinmux = <PINMUX_GPIO9__FUNC_GPIO9>;
			slew-rate = <0>;
			bias-disable;
		};
	};
};
/* accdet end */

//#ifdef OPLUS_FEATURE_FINGERPRINT
/* FINGERPRINT start */
&spi1 {
	#address-cells = <1>;
	#size-cells = <0>;
	status = "okay";
	finger_spi@0 {
		compatible = "mediatek,fingerspi-fp";
		reg = <0>;
		spi-id = <1>;
		spi-max-frequency = <8000000>;
		netlink-event = <30>;
		spi-irq = <122>;
		spi-reg = <0x11010000>;
		goodix,pw_en = <&pio 18 0x00>;
		status = "okay";
		power_source_1 {
			power-mode = <2>;
			power-name = "goodix,pw_en";
			delay-time = <0>;
		};
	};
};

&silead_fp {
        sil,silead_irq = <&pio 5 0x00>;
	sil,ldo_disable = <1>;
        fpc,vdd-en = <&pio 18 0x00>;
        pinctrl-names = "default", "rst-low", "rst-high",
                        "irq-init", "power_high","power_low","finger_cs_gpio","finger_cs_func";
        pinctrl-0 = <&silfp_default>;
        pinctrl-1 = <&silfp_rst_low>;
        pinctrl-2 = <&silfp_rst_high>;
        pinctrl-3 = <&silfp_irq>;
        pinctrl-4 = <&finger_cs_func_en>, <&fingerfp_power_high>;
        pinctrl-5 = <&finger_cs_gpio_en>, <&fingerfp_power_low>;
        status = "okay";
};

&pio {
        silfp_default: silfpdefault {
        };
        silfp_rst_low: state_reset_low {
                pins_cmd_dat {
                        pinmux = <PINMUX_GPIO7__FUNC_GPIO7>;
                        output-low;
                };
        };
        silfp_rst_high: state_reset_high {
                pins_cmd_dat {
                        pinmux = <PINMUX_GPIO7__FUNC_GPIO7>;
                        output-high;
                };
        };
        silfp_irq: fp_eint@5 {
                pins_cmd_dat {
                        pinmux = <PINMUX_GPIO5__FUNC_GPIO5>;
                        input;
                        bias-disable;
                };
        };
        fingerfp_power_high: state_power_high {
                pins_cmd_dat {
                        pinmux = <PINMUX_GPIO20__FUNC_GPIO20>;
                        output-high;
                };
        };
        fingerfp_power_low: state_power_low {
                pins_cmd_dat {
                        pinmux = <PINMUX_GPIO20__FUNC_GPIO20>;
                        output-low;
                };
        };
        finger_cs_gpio_en: finger_cs_gpio_en {
                pins_cmd_dat {
                        pinmux = <PINMUX_GPIO26__FUNC_GPIO26>;
                        output-low;
                };
        };
        finger_cs_func_en: finger_cs_func_en {
                pins_cmd_dat {
                         pinmux = <PINMUX_GPIO26__FUNC_SPI1_A_CSB>;
                         drive-strength = <3>;
                };
        };
};

&oplus_fp_common {
	compatible = "oplus,fp_common"; //Manufacture, and Model
	oplus,fp_gpio_num = <1>;
	oplus,fp_gpio_0 = <&pio 166 0x00>;
	pinctrl-names = "gpio_id0_up", "gpio_id0_down";
	pinctrl-0 = <&gpio_id0_up>;
	pinctrl-1 = <&gpio_id0_down>;
	oplus,one_gpio_for_three_ic = <1>;
	FP_GSL_6150 {
		oplus,fp-id = <0>; /* fp id mapping table Q:0*/
		vendor-chip = <21>; /* please refer to the struct fp_vendor_t in oppo_fp_commmon.n */
		eng-menu = "-1,-1"; /* represents SNR, inclination test item in engineer menu, and 0/1 means off/on */
		chip-name = "S_6150";  /* /proc/fp_id, will be displayed in engineer menu  */
	};
	FP_FPC_1511 {
		oplus,fp-id = <2>; /* fp id mapping table Q:1*/
		vendor-chip = <28>; /* please refer to the struct fp_vendor_t in oppo_fp_commmon.n */
		eng-menu = "-1,-1"; /* represents SNR, inclination test item in engineer menu, and 0/1 means off/on */
		chip-name = "F_1521";  /* /proc/fp_id, will be displayed in engineer menu  */
	};
	FP_CHIPONE_7332 {
		oplus,fp-id = <1>; /* fp id mapping table Q:2*/
		vendor-chip = <24>; /* please refer to the struct fp_vendor_t in oppo_fp_commmon.n */
		eng-menu = "-1,-1"; /* represents SNR, inclination test item in engineer menu, and 0/1 means off/on */
		chip-name = "C_7332";  /* /proc/fp_id, will be displayed in engineer menu  */
	};
};

&pio {
	gpio_id0_up: gpio_id0_up {
		pins_cmd_dat {
			pinmux = <PINMUX_GPIO166__FUNC_GPIO166>;
			input;
			bias-pull-up;
			input-enable;
		};
	};
	gpio_id0_down: gpio_id0_down {
		pins_cmd_dat {
			pinmux = <PINMUX_GPIO166__FUNC_GPIO166>;
			input;
			bias-pull-down;
			input-enable;
		};
	};
};

&fpsensor_finger {
	chipone,ldo_disable = <1>;
	chipone,irq-gpio = <&pio 5 0x00>;
	interrupt-parent = <&pio>;
	interrupts = <5 IRQ_TYPE_EDGE_RISING>;
	debounce = <2 0>;
	pinctrl-names = "fpsensor_finger_rst_low","fpsensor_finger_rst_high","power_low","power_high","fpsensor_cs_gpio","fpsensor_cs_func","irq-init";
	pinctrl-0 = <&fpsensor_finger_rst_mode_en0>;
	pinctrl-1 = <&fpsensor_finger_rst_mode_en1>;
	pinctrl-2 = <&fpsensor_finger_pwr_mode_en0>;
	pinctrl-3 = <&fpsensor_finger_pwr_mode_en1>;
	pinctrl-4 = <&fpsensor_cs_gpio_en>;
	pinctrl-5 = <&fpsensor_cs_func_en>;
	pinctrl-6 = <&fpsensor_irq_cfg>;
	status = "okay";
};

&pio {
	fpsensor_finger_rst_mode_en0: fpsensor_finger_rst_mode_en0 {
		pins_cmd_dat {
			pinmux = <PINMUX_GPIO7__FUNC_GPIO7>;
			output-low;
		};
	};
	fpsensor_finger_rst_mode_en1: fpsensor_finger_rst_mode_en1 {
		pins_cmd_dat {
			pinmux = <PINMUX_GPIO7__FUNC_GPIO7>;
			output-high;
		};
	};

	fpsensor_finger_pwr_mode_en0: fpsensor_finger_pwr_mode_en0 {
		pins_cmd_dat {
			pinmux = <PINMUX_GPIO20__FUNC_GPIO20>;
			output-low;
		};
	};
	fpsensor_finger_pwr_mode_en1: fpsensor_finger_pwr_mode_en1 {
		pins_cmd_dat {
			pinmux = <PINMUX_GPIO20__FUNC_GPIO20>;
			output-high;
		};
	};
	fpsensor_cs_gpio_en: fpsensor_cs_gpio_en {
		pins_cmd_dat {
			pinmux = <PINMUX_GPIO26__FUNC_GPIO26>;
			output-low;
		};
	};
	fpsensor_cs_func_en: fpsensor_cs_func_en {
		pins_cmd_dat {
			pinmux = <PINMUX_GPIO26__FUNC_SPI1_A_CSB>;
			drive-strength = <3>;
		};
	};
	fpsensor_irq_cfg: fpsensor_irq_cfg {
		pins_cmd_dat {
			pinmux = <PINMUX_GPIO5__FUNC_GPIO5>;
			input;
			bias-disable;
		};
	};
};

&fpc_interrupt {
	fpc,irq-gpio    = <&pio 5 0x00>;
	fpc,reset-gpio  = <&pio 7 0x00>;
	fpc,vdd-en = <&pio 18 0x00>;
	fpc,gpio_cs = <&pio 26 0x00>;
	fpc,use_gpio_power_enable = <1>;
	pinctrl-names = "irq_default", "fpc_cs_gpio","fpc_cs_func";
	pinctrl-0 = <&fpc_irq_default>/*,<&fpc_pwr_default>*/;
	pinctrl-1 = <&gpio_fpc_cs_gpio>;
	pinctrl-2 = <&gpio_fpc_cs_func>;
	status = "okay";
	power_source_1 {
		power-mode = <2>;
		power-name = "fpc,vdd-en";
		poweron-level = <0>;
		delay-time = <0>;
	};
};

&pio {
	fpc_irq_default: fpc_irq_default {
		pins_cmd_dat {
			pinmux = <PINMUX_GPIO5__FUNC_GPIO5>;
			input;
			bias-pull-up;
		};
	};
	gpio_fpc_cs_gpio: gpio_fpc_cs_gpio {
		pins_cmd_dat {
			pinmux = <PINMUX_GPIO26__FUNC_GPIO26>;
			output-low;
		};
	};
	gpio_fpc_cs_func: gpio_fpc_cs_func {
		pins_cmd_dat {
			pinmux = <PINMUX_GPIO26__FUNC_SPI1_A_CSB>;
			drive-strength = <3>;
		};
	};
};

/* FINGERPRINT end */
//#endif /*OPLUS_FEATURE_FINGERPRINT*/


/* IRTX GPIO end */
&irtx_pwm {
	pinctrl-names = "irtx_gpio_led_default", "irtx_gpio_led_set";
	pinctrl-0 = <&irtx_gpio_led_default>;
	pinctrl-1 = <&irtx_gpio_led_set>;
	status = "okay";
};
&pio {
	irtx_gpio_led_default:irtx_gpio_led_def@gpio90 {
		pins_cmd_dat {
			pinmux = <PINMUX_GPIO90__FUNC_GPIO90>;
			slew-rate = <1>;
			bias-disable;
			output-low;
			input-schmitt-enable = <0>;
		};
	};

	irtx_gpio_led_set:irtx_gpio_led_set@gpio90 {
		pins_cmd_dat {
			pinmux = <PINMUX_GPIO90__FUNC_PWM0>;
			slew-rate = <1>;
			output-high;
		};
	};
};
/* IRTX GPIO Settings -End */

/* AUDIO GPIO standardization */
&audgpio {
	pinctrl-names = "aud_clk_mosi_off",
			"aud_clk_mosi_on",
			"aud_clk_miso_off",
			"aud_clk_miso_on",
			"aud_dat_mosi_off",
			"aud_dat_mosi_on",
			"aud_dat_miso_off",
			"aud_dat_miso_on";
	pinctrl-0 = <&aud_clk_mosi_off>;
	pinctrl-1 = <&aud_clk_mosi_on>;
	pinctrl-2 = <&aud_clk_miso_off>;
	pinctrl-3 = <&aud_clk_miso_on>;
	pinctrl-4 = <&aud_dat_mosi_off>;
	pinctrl-5 = <&aud_dat_mosi_on>;
	pinctrl-6 = <&aud_dat_miso_off>;
	pinctrl-7 = <&aud_dat_miso_on>;

	status = "okay";
};

&pio {
	aud_clk_mosi_off: aud_clk_mosi_off {
		pins_cmd0_dat {
			pinmux = <PINMUX_GPIO136__FUNC_GPIO136>;
		};
	};

	aud_clk_mosi_on: aud_clk_mosi_on {
		pins_cmd0_dat {
			pinmux = <PINMUX_GPIO136__FUNC_AUD_CLK_MOSI>;
		};
	};

	aud_clk_miso_off: aud_clk_miso_off {
		pins_cmd0_dat {
			pinmux = <PINMUX_GPIO140__FUNC_GPIO140>;
		};
	};

	aud_clk_miso_on: aud_clk_miso_on {
		pins_cmd0_dat {
			pinmux = <PINMUX_GPIO140__FUNC_AUD_CLK_MISO>;
		};
	};

	aud_dat_mosi_off: aud_dat_mosi_off {
		pins_cmd1_dat {
			pinmux = <PINMUX_GPIO138__FUNC_GPIO138>;
			input-enable;
			slew-rate = <0>;
			bias-disable;
		};
		pins_cmd2_dat {
			pinmux = <PINMUX_GPIO139__FUNC_GPIO139>;
			input-enable;
			slew-rate = <0>;
			bias-disable;
		};
	};

	aud_dat_mosi_on: aud_dat_mosi_on {
		pins_cmd1_dat {
			pinmux = <PINMUX_GPIO138__FUNC_AUD_DAT_MOSI0>;
		};
		pins_cmd2_dat {
			pinmux = <PINMUX_GPIO139__FUNC_AUD_DAT_MOSI1>;
		};
	};

	aud_dat_miso_off: aud_dat_miso_off {
		pins_cmd1_dat {
			pinmux = <PINMUX_GPIO142__FUNC_GPIO142>;
			input-enable;
			slew-rate = <0>;
			bias-disable;
		};
		pins_cmd2_dat {
			pinmux = <PINMUX_GPIO143__FUNC_GPIO143>;
			input-enable;
			slew-rate = <0>;
			bias-disable;
		};
	};

	aud_dat_miso_on: aud_dat_miso_on {
		pins_cmd1_dat {
			pinmux = <PINMUX_GPIO142__FUNC_AUD_DAT_MISO0>;
		};
		pins_cmd2_dat {
			pinmux = <PINMUX_GPIO143__FUNC_AUD_DAT_MISO1>;
		};
	};
};
/* AUDIO end */

#include "mediatek/rt9471_single.dtsi"
#include "mediatek/sgm41512.dtsi"
#include "mediatek/bq25910.dtsi"
#include "mediatek/bq2589x.dtsi"

&mt6370_typec {
	mt6370pd,intr_gpio_num = <41>; /* direct defined GPIO num */
	mt6370pd,intr_gpio = <&pio 41 0x0>;
};

&uart0 {
	pinctrl-names = "uart0_rx_gpio",
		"uart0_tx_gpio";
	pinctrl-0 = <&uart0_rx_gpio_input>;
	pinctrl-1 = <&uart0_tx_gpio_input>;
	status = "okay";
};
&pio {
	uart0_rx_gpio_input:uart0_rx_gpio@gpio95 {
		pins_cmd_dat {
			pinmux = <PINMUX_GPIO95__FUNC_GPIO95>;
			input-enable;
			bias-pull-down;
		};
	};
	uart0_tx_gpio_input:uart0_tx_gpio@gpio96 {
		pins_cmd_dat {
			pinmux = <PINMUX_GPIO96__FUNC_GPIO96>;
			input-enable;
			bias-pull-down;
		};
	};
};

&otg_iddig {
	compatible = "mediatek,usb_iddig_bi_eint";
	interrupt-parent = <&pio>;
	interrupts = <147 IRQ_TYPE_LEVEL_LOW 147 0>;
	pinctrl-names = "otg_iddg_high","otg_gpio_low";
	pinctrl-0 = <&otg_iddg_high>;
	pinctrl-1 = <&otg_gpio_low>;
};

&pio {
	otg_iddg_high:otg_iddg_high {
		pins_cmd_dat {
			pinmux = <PINMUX_GPIO41__FUNC_IDDIG>;
			input;
			bias-pull-up;
		};
	};

	otg_gpio_low:otg_gpio_low {
		pins_cmd_dat {
			pinmux = <PINMUX_GPIO41__FUNC_GPIO41>;
			output-low;
		};
	};
};


//#ifdef OPLUS_BUG_STABILITY
&mtkfb {
        pinctrl-names = "lcm_rst_out0_gpio", "lcm_rst_out1_gpio", "lcd_bias_enp0_gpio", "lcd_bias_enp1_gpio",
			"lcd_bias_enn0_gpio", "lcd_bias_enn1_gpio", "lcd_vddio18_en0_gpio", "lcd_vddio18_en1_gpio";

	pinctrl-0 = <&mtkfb_pins_lcm_reset0>;
	pinctrl-1 = <&mtkfb_pins_lcm_reset1>;
	pinctrl-2 = <&mtkfb_pins_lcd_bias_enp0>;
	pinctrl-3 = <&mtkfb_pins_lcd_bias_enp1>;
	pinctrl-4 = <&mtkfb_pins_lcd_bias_enn0>;
	pinctrl-5 = <&mtkfb_pins_lcd_bias_enn1>;
	//pinctrl-6 = <&mtkfb_pins_lcd_vddio18_en0>;
	//pinctrl-7 = <&mtkfb_pins_lcd_vddio18_en1>;
	oplus_display_twelvebits_support;
	oplus_display_local_dre_support;
	oplus_display_lcd_dimming_support;
	oplus_display_dyn_mipi_support;
	status = "okay";
};

&pio {
	mtkfb_pins_lcm_reset0: lcm_rst_out0_gpio {
			pins_cmd_dat {
					pinmux = <PINMUX_GPIO45__FUNC_GPIO45>;
					slew-rate = <1>;
					output-low;
			};
	};
	mtkfb_pins_lcm_reset1: lcm_rst_out1_gpio {
			pins_cmd_dat {
					pinmux = <PINMUX_GPIO45__FUNC_GPIO45>;
					slew-rate = <1>;
					output-high;
			};
	};

	mtkfb_pins_lcd_bias_enp0: lcd_bias_enp0_gpio {
                pins_cmd_dat {
                        pinmux = <PINMUX_GPIO150__FUNC_GPIO150>;
                        slew-rate = <1>;
                        output-low;
                };
        };
	mtkfb_pins_lcd_bias_enp1: lcd_bias_enp1_gpio {
                pins_cmd_dat {
                        pinmux = <PINMUX_GPIO150__FUNC_GPIO150>;
                        slew-rate = <1>;
                        output-high;
                };
        };

	mtkfb_pins_lcd_bias_enn0: lcd_bias_enn0_gpio {
                pins_cmd_dat {
                        pinmux = <PINMUX_GPIO151__FUNC_GPIO151>;
                        slew-rate = <1>;
                        output-low;
                };
        };
	mtkfb_pins_lcd_bias_enn1: lcd_bias_enn1_gpio {
                pins_cmd_dat {
                        pinmux = <PINMUX_GPIO151__FUNC_GPIO151>;
                        slew-rate = <1>;
                        output-high;
                };
        };
};
//#endif

#include "mediatek/bat_setting/mt6765_battery_prop_21281.dtsi"
#include "oppo6765_21281/cust.dtsi"
#include "mediatek/cust_mt6765_camera_yogurta.dtsi"
/*End of this file, DO NOT ADD ANYTHING HERE*/
